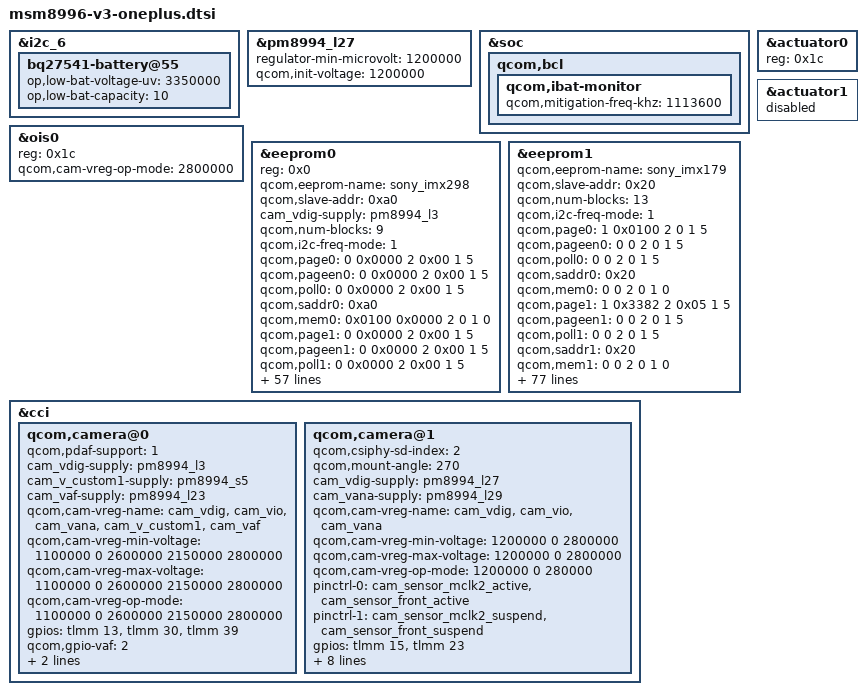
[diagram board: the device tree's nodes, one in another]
/*
 * Copyright (c) 2015 The Linux Foundation. All rights reserved.
 *
 * This program is free software; you can redistribute it and/or modify
 * it under the terms of the GNU General Public License version 2 and
 * only version 2 as published by the Free Software Foundation.
 *
 * This program is distributed in the hope that it will be useful,
 * but WITHOUT ANY WARRANTY; without even the implied warranty of
 * MERCHANTABILITY or FITNESS FOR A PARTICULAR PURPOSE.  See the
 * GNU General Public License for more details.
 */

#include "msm8996-oneplus.dtsi"

&i2c_6 {
	bq27541-battery@55 {
		op,low-bat-voltage-uv=<3350000>;
		op,low-bat-capacity=<10>;
	};
};

&pm8994_l27 {
	regulator-min-microvolt = <1200000>;
	qcom,init-voltage = <1200000>;
};

&soc {
	qcom,bcl {
		qcom,ibat-monitor {
			qcom,mitigation-freq-khz = <1113600>;
		};
	};
};

&actuator0 {
	reg = <0x1c>;
	/delete-property/ cam_vaf-supply;
	/delete-property/ qcom,cam-vreg-name;
	/delete-property/ qcom,cam-vreg-min-voltage;
	/delete-property/ qcom,cam-vreg-max-voltage;
	/delete-property/ qcom,cam-vreg-op-mode;
};

&actuator1 {
	status = "disabled";
};

&ois0 {
	reg = <0x1c>;
	qcom,cam-vreg-op-mode = <2800000>;
};

&eeprom0 {
	reg = <0x0>;
	qcom,eeprom-name = "sony_imx298";
	qcom,slave-addr = <0xa0>;
	cam_vdig-supply = <&pm8994_l3>;

	qcom,num-blocks = <9>;
	qcom,i2c-freq-mode = <1>;
	qcom,page0 = <0 0x0000 2 0x00 1 5>;
	qcom,pageen0 = <0 0x0000 2 0x00 1 5>;
	qcom,poll0 = <0 0x0000 2 0x00 1 5>;
	qcom,saddr0 = <0xa0>;
	qcom,mem0 = <0x0100 0x0000 2 0 1 0>;
	qcom,page1 = <0 0x0000 2 0x00 1 5>;
	qcom,pageen1 = <0 0x0000 2 0x00 1 5>;
	qcom,poll1 = <0 0x0000 2 0x00 1 5>;
	qcom,saddr1 = <0xa0>;
	qcom,mem1 = <0x0100 0x0100 2 0 1 0>;
	qcom,page2 = <0 0x0000 2 0x00 1 5>;
	qcom,pageen2 = <0 0x0000 2 0x00 1 5>;
	qcom,poll2 = <0 0x0000 2 0x00 1 5>;
	qcom,saddr2 = <0xa0>;
	qcom,mem2 = <0x0100 0x0200 2 0 1 0>;
	qcom,page3 = <0 0x0000 2 0x00 1 5>;
	qcom,pageen3 = <0 0x0000 2 0x00 1 5>;
	qcom,poll3 = <0 0x0000 2 0x00 1 5>;
	qcom,saddr3 = <0xa0>;
	qcom,mem3 = <0x0100 0x0300 2 0 1 0>;
	qcom,page4 = <0 0x0000 2 0x00 1 5>;
	qcom,pageen4 = <0 0x0000 2 0x00 1 5>;
	qcom,poll4 = <0 0x0000 2 0x00 1 5>;
	qcom,saddr4 = <0xa0>;
	qcom,mem4 = <0x0100 0x0400 2 0 1 0>;
	qcom,page5 = <0 0x0000 2 0x00 1 5>;
	qcom,pageen5 = <0 0x0000 2 0x00 1 5>;
	qcom,poll5 = <0 0x0000 2 0x00 1 5>;
	qcom,saddr5 = <0xa0>;
	qcom,mem5 = <0x0100 0x0500 2 0 1 0>;
	qcom,page6 = <0 0x0000 2 0x00 1 5>;
	qcom,pageen6 = <0 0x0000 2 0x00 1 5>;
	qcom,poll6 = <0 0x0000 2 0x00 1 5>;
	qcom,saddr6 = <0xa0>;
	qcom,mem6 = <0x0100 0x0600 2 0 1 0>;
	qcom,page7 = <0 0x0000 2 0x00 1 5>;
	qcom,pageen7 = <0 0x0000 2 0x00 1 5>;
	qcom,poll7 = <0 0x0000 2 0x00 1 5>;
	qcom,saddr7 = <0xa0>;
	qcom,mem7 = <0x0100 0x0700 2 0 1 0>;		
	qcom,page8 = <0 0x0000 2 0x00 1 5>;
	qcom,pageen8 = <0 0x0000 2 0x00 1 5>;
	qcom,poll8 = <0 0x0000 2 0x00 1 5>;
	qcom,saddr8 = <0xa0>;
	qcom,mem8 = <0x0100 0x0800 2 0 1 0>;

	cam_vio-supply = <&pm8994_lvs1>;
	cam_vana-supply = <&pm8994_l17>;
	/delete-property/ cam_vaf-supply;
	qcom,cam-vreg-name = "cam_vdig", "cam_vio", "cam_vana";
	qcom,cam-vreg-min-voltage = <1100000 0 2600000>;
	qcom,cam-vreg-max-voltage = <1100000 0 2600000>;
	qcom,cam-vreg-op-mode = <1100000 0 2600000>;
	gpios = <&tlmm 13 0>,
		<&tlmm 30 0>;
	/delete-property/ qcom,gpio-standby;
	qcom,gpio-req-tbl-num = <0 1>;
	qcom,gpio-req-tbl-flags = <1 0>;
	qcom,gpio-req-tbl-label = "CAMIF_MCLK0",
				  "CAM_RESET0";
	qcom,cam-power-seq-type = "sensor_vreg","sensor_vreg", "sensor_vreg", "sensor_gpio", "sensor_clk";
	qcom,cam-power-seq-val = "cam_vana", "cam_vdig", "cam_vio", "sensor_gpio_reset", "sensor_cam_mclk";
	qcom,cam-power-seq-cfg-val = <0 0 0 1 24000000>;
	qcom,cam-power-seq-delay =   <1 1 1 1 1>;
	qcom,clock-rates = <24000000 0>;
};

&eeprom1 {
	qcom,eeprom-name = "sony_imx179";
	qcom,slave-addr = <0x20>;
	qcom,num-blocks = <13>;
	qcom,i2c-freq-mode = <1>;
	qcom,page0 = <1 0x0100 2 0 1 5>;
	qcom,pageen0 = <0 0 2 0 1 5>;
	qcom,poll0 = <0 0 2 0 1 5>;
	qcom,saddr0 = <0x20>;
	qcom,mem0 = <0 0 2 0 1 0>;
	qcom,page1 = <1 0x3382 2 0x05 1 5>;
	qcom,pageen1 = <0 0 2 0 1 5>;
	qcom,poll1 = <0 0 2 0 1 5>;
	qcom,saddr1 = <0x20>;
	qcom,mem1 = <0 0 2 0 1 0>;
	qcom,page2 = <1 0x3383 2 0xa0 1 5>;
	qcom,pageen2 = <0 0 2 0 1 5>;
	qcom,poll2 = <0 0 2 0 1 5>;
	qcom,saddr2 = <0x20>;
	qcom,mem2 = <0 0 2 0 1 0>;
	qcom,page3 = <1 0x3368 2 0x18 1 5>;
	qcom,pageen3 = <0 0 2 0 1 5>;
	qcom,poll3 = <0 0 2 0 1 5>;
	qcom,saddr3 = <0x20>;
	qcom,mem3 = <0 0 2 0 1 0>;
	qcom,page4 = <1 0x3369 2 0 1 5>;
	qcom,pageen4 = <0 0 2 0 1 5>;
	qcom,poll4 = <0 0 2 0 1 5>;
	qcom,saddr4 = <0x20>;
	qcom,mem4 = <0 0 2 0 1 0>;
	qcom,page5 = <1 0x3380 2 0 1 5>;
	qcom,pageen5 = <0 0 2 0 1 5>;
	qcom,poll5 = <0 0 2 0 1 5>;
	qcom,saddr5 = <0x20>;
	qcom,mem5 = <0 0 2 0 1 0>;
	qcom,page6 = <1 0x3400 2 0x01 1 5>;
	qcom,pageen6 = <0 0 2 0 1 5>;
	qcom,poll6 = <0 0 2 0 1 5>;
	qcom,saddr6 = <0x20>;
	qcom,mem6 = <0 0 2 0 1 0>;
	qcom,page7 = <1 0x3402 2 0x01 1 5>;
	qcom,pageen7 = <0 0 2 0 1 5>;
	qcom,poll7 = <0 0 2 0 1 5>;
	qcom,saddr7 = <0x20>;
	qcom,mem7 = <0 0 2 0 1 0>;
	qcom,page8 = <0 0 2 0 1 5>;
	qcom,pageen8 = <0 0 2 0 1 5>;
	qcom,poll8 = <0 0 2 0 1 5>;
	qcom,saddr8 = <0x20>;
	qcom,mem8 = <0x40 0x3404 2 0 1 0>;
	qcom,page9 = <1 0x3402 2 0x02 1 5>;
	qcom,pageen9 = <0 0 2 0 1 5>;
	qcom,poll9 = <0 0 2 0 1 5>;
	qcom,saddr9 = <0x20>;
	qcom,mem9 = <0 0 2 0 1 0>;
	qcom,page10 = <0 0 2 0 1 5>;
	qcom,pageen10 = <0 0 2 0 1 5>;
	qcom,poll10 = <0 0 2 0 1 5>;
	qcom,saddr10 = <0x20>;
	qcom,mem10 = <0x40 0x3404 2 0 1 0>;
	qcom,page11 = <1 0x3402 2 0x03 1 5>;
	qcom,pageen11 = <0 0 2 0 1 5>;
	qcom,poll11 = <0 0 2 0 1 5>;
	qcom,saddr11 = <0x20>;
	qcom,mem11 = <0 0 2 0 1 0>;
	qcom,page12 = <0 0 2 0 1 5>;
	qcom,pageen12 = <0 0 2 0 1 5>;
	qcom,poll12 = <0 0 2 0 1 5>;
	qcom,saddr12 = <0x20>;
	qcom,mem12 = <0x40 0x3404 2 0 1 0>;
	qcom,cam-vreg-min-voltage = <1200000 0 2800000>;
	qcom,cam-vreg-max-voltage = <1200000 0 2800000>;
	qcom,cam-vreg-op-mode = <1200000 0 280000>;
	pinctrl-0 = <&cam_sensor_mclk2_active &cam_sensor_front_active>;
	pinctrl-1 = <&cam_sensor_mclk2_suspend &cam_sensor_front_suspend>;
	gpios = <&tlmm 15 0>,
		<&tlmm 23 0>;
	/delete-property/ qcom,gpio-standby;
	qcom,gpio-req-tbl-num = <0 1>;
	qcom,gpio-req-tbl-flags = <1 0>;
	qcom,gpio-req-tbl-label = "CAMIF_MCLK2",
				  "CAM_RESET2";
	qcom,sensor-position = <1>;
	qcom,sensor-mode = <1>;
	qcom,cam-power-seq-type = "sensor_vreg","sensor_vreg", "sensor_vreg", "sensor_gpio", "sensor_clk";
	qcom,cam-power-seq-val = "cam_vana", "cam_vio", "cam_vdig", "sensor_gpio_reset", "sensor_cam_mclk";
	qcom,cam-power-seq-cfg-val = <0 0 0 1 24000000>;
	qcom,cam-power-seq-delay =   <0 0 0 0 0>;
	qcom,clock-rates = <24000000 0>;
};

&cci {
	qcom,camera@0 {
                qcom,pdaf-support = <1>;
		cam_vdig-supply = <&pm8994_l3>;
		cam_v_custom1-supply = <&pm8994_s5>;
		cam_vaf-supply = <&pm8994_l23>;
		/delete-property/ qcom,vdd-cx-supply;
		/delete-property/ qcom,vdd-cx-name;
		qcom,cam-vreg-name = "cam_vdig", "cam_vio", "cam_vana", "cam_v_custom1", "cam_vaf";
		qcom,cam-vreg-min-voltage = <1100000 0 2600000 2150000 2800000>;
		qcom,cam-vreg-max-voltage = <1100000 0 2600000 2150000 2800000>;
		qcom,cam-vreg-op-mode = <1100000 0 2600000 2150000 2800000>;
		gpios = <&tlmm 13 0>,
			<&tlmm 30 0>,
			<&tlmm 39 0>;
		/delete-property/ qcom,gpio-standby;
		qcom,gpio-vaf = <2>;
		qcom,gpio-req-tbl-label = "CAMIF_MCLK0",
					  "CAM_RESET0",
					  "CAM_VAF0";
	};

	qcom,camera@1 {
		qcom,csiphy-sd-index = <2>;
		qcom,mount-angle = <270>;
		cam_vdig-supply = <&pm8994_l27>;
		cam_vana-supply = <&pm8994_l29>;
		qcom,cam-vreg-name = "cam_vdig", "cam_vio", "cam_vana";
		qcom,cam-vreg-min-voltage = <1200000 0 2800000>;
		qcom,cam-vreg-max-voltage = <1200000 0 2800000>;
		qcom,cam-vreg-op-mode = <1200000 0 280000>;
		pinctrl-0 = <&cam_sensor_mclk2_active &cam_sensor_front_active>;
		pinctrl-1 = <&cam_sensor_mclk2_suspend &cam_sensor_front_suspend>;
		gpios = <&tlmm 15 0>,
			<&tlmm 23 0>;
		/delete-property/ qcom,gpio-standby;
		qcom,gpio-req-tbl-num = <0 1>;
		qcom,gpio-req-tbl-flags = <1 0>;
		qcom,gpio-req-tbl-label = "CAMIF_MCLK2",
					  "CAM_RESET2";
		qcom,sensor-mode = <1>;
		clocks = <&clock_mmss clk_mclk2_clk_src>,
			<&clock_mmss clk_camss_mclk2_clk>;
		support-front-camera = "IMX179";
	};
};
